# CC2538NF53 register map
File version: 1.0
CPU: CM3 1.0, other endian, MPU, FPU, 3 interrupt priority bits
Registers are 32-bit, read-write, reset 0x0 unless marked. A register's access mark holds for its fields unless they carry their own. Offsets are from the block's base; [hi:lo] are bit positions.

## I2CS — Register fields should be considered static unless otherwise noted as dynamic.
Base 0x40020800
0x00 OAR — I2C slave own address This register consists of seven address bits that identify the CC2538 I2C device on the I2C bus.
  [6:0] OAR — [6:0] I2C slave own address This field specifies bits A6 through A0 of the slave address.
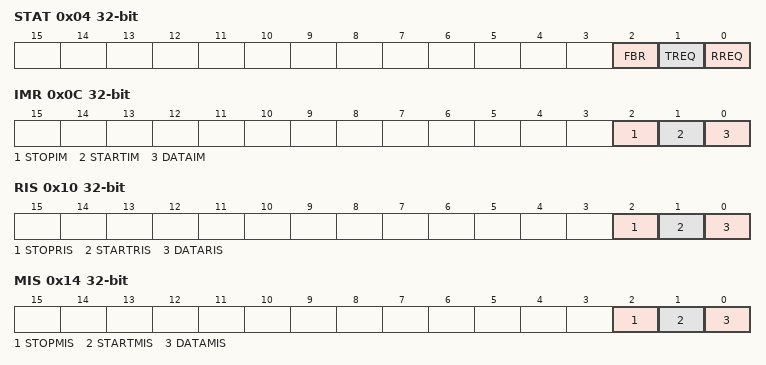
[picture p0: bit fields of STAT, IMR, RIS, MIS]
0x04 STAT — I2C slave control and status This register functions as a control register when written, and a status register when read.
  [2] FBR — [2:2] First byte received 1: The first byte following the slave's own address has been received. 0: The first byte has not been received. This bit is only valid when the RREQ bit is set and is automatically cleared when data has been read from the I2CSDR register. Note: This bit is not used for slave transmit operations.
  [1] TREQ — [1:1] Transmit request 1: The I2C controller has been addressed as a slave transmitter and is using clock stretching to delay the master until data has been written to the I2CSDR register. 0: No outstanding transmit request.
  [0] RREQ — [0:0] Receive request 1: The I2C controller has outstanding receive data from the I2C master and is using clock stretching to delay the master until data has been read from the I2CSDR register. 0: No outstanding receive data
0x04 CTRL — I2C slave control and status This register functions as a control register when written, and a status register when read.
  [0] DA — [0:0] Device active 0: Disables the I2C slave operation 1: Enables the I2C slave operation
0x08 DR — I2C slave data This register contains the data to be transmitted when in the slave transmit state, and the data received when in the slave receive state.
  [7:0] DATA — [7:0] Data for transfer This field contains the data for transfer during a slave receive or transmit operation.
0x0C IMR — I2C slave interrupt mask This register controls whether a raw interrupt is promoted to a controller interrupt.
  [2] STOPIM — [2:2] Stop condition interrupt mask 1: The STOP condition interrupt is sent to the interrupt controller when the STOPRIS bit in the I2CSRIS register is set. 0: The STOPRIS interrupt is supressed and not sent to the interrupt controller.
  [1] STARTIM — [1:1] Start condition interrupt mask 1: The START condition interrupt is sent to the interrupt controller when the STARTRIS bit in the I2CSRIS register is set. 0: The STARTRIS interrupt is supressed and not sent to the interrupt controller.
  [0] DATAIM — [0:0] Data interrupt mask 1: The data received or data requested interrupt is sent to the interrupt controller when the DATARIS bit in the I2CSRIS register is set. 0: The DATARIS interrupt is surpressed and not sent to the interrupt controller.
0x10 RIS — I2C slave raw interrupt status This register specifies whether an interrupt is pending.
  [2] STOPRIS — [2:2] Stop condition raw interrupt status 1: A STOP condition interrupt is pending. 0: No interrupt This bit is cleared by writing 1 to the STOPIC bit in the I2CSICR register.
  [1] STARTRIS — [1:1] Start condition raw interrupt status 1: A START condition interrupt is pending. 0: No interrupt This bit is cleared by writing 1 to the STARTIC bit in the I2CSICR register.
  [0] DATARIS — [0:0] Data raw interrupt status 1: A data received or data requested interrupt is pending. 0: No interrupt This bit is cleared by writing 1 to the DATAIC bit in the I2CSICR register.
0x14 MIS — I2C slave masked interrupt status This register specifies whether an interrupt was signaled.
  [2] STOPMIS — [2:2] Stop condition masked interrupt status 1: An unmasked STOP condition interrupt is pending. 0: An interrupt has not occurred or is masked. This bit is cleared by writing 1 to the STOPIC bit in the I2CSICR register.
  [1] STARTMIS — [1:1] Start condition masked interrupt status 1: An unmasked START condition interrupt is pending. 0: An interrupt has not occurred or is masked. This bit is cleared by writing 1 to the STARTIC bit in the I2CSICR register.
  [0] DATAMIS — [0:0] Data masked interrupt status 1: An unmasked data received or data requested interrupt is pending. 0: An interrupt has not occurred or is masked. This bit is cleared by writing 1 to the DATAIC bit in the I2CSICR register.
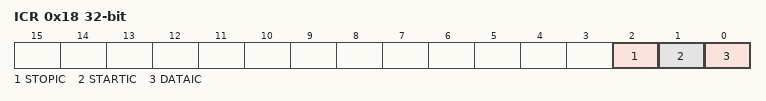
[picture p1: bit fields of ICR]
0x18 ICR — I2C slave interrupt clear This register clears the raw interrupt. A read of this register returns no meaningful data.
  [2] STOPIC — [2:2] Stop condition interrupt clear Writing 1 to this bit clears the STOPRIS bit in the I2CSRIS register and the STOPMIS bit in the I2CSMIS register. A read of this register returns no meaningful data.
  [1] STARTIC — [1:1] Start condition interrupt vlear Writing 1 to this bit clears the STARTRIS bit in the I2CSRIS register and the STARTMIS bit in the I2CSMIS register. A read of this register returns no meaningful data.
  [0] DATAIC — [0:0] Data interrupt clear Writing 1 to this bit clears the DATARIS bit in the I2CSRIS register and the DATAMIS bit in the I2CSMIS register. A read of this register returns no meaningful data.
